VERSION "1.0"

NS_ :

BS_:

BU_: Transmitter

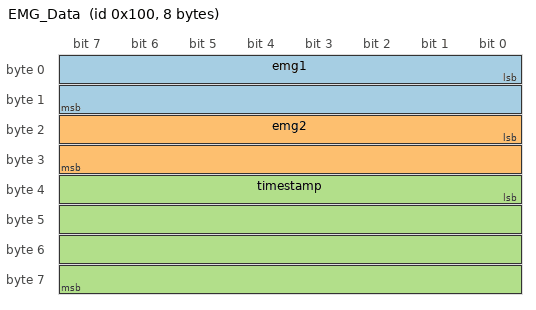
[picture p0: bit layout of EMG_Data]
BO_ 256 EMG_Data: 8 Transmitter
 SG_ emg1 : 0|16@1+ (1,0) [0|65535] "" Vector__XXX
 SG_ emg2 : 16|16@1+ (1,0) [0|65535] "" Vector__XXX
 SG_ timestamp : 32|32@1+ (1,0) [0|4294967295] "ms" Vector__XXX

BO_ 257 HeartRate_Data: 8 Transmitter
 SG_ heart_rate : 0|8@1+ (1,0) [0|255] "bpm" Vector__XXX
 SG_ timestamp : 8|32@1+ (1,0) [0|4294967295] "ms" Vector__XXX

CM_ SG_ 256 emg1 "EMG sensor 1 value (raw)";
CM_ SG_ 256 emg2 "EMG sensor 2 value (raw)";
CM_ SG_ 256 timestamp "Timestamp of EMG reading (ms)";
CM_ SG_ 257 heart_rate "Heart rate value (bpm)";
CM_ SG_ 257 timestamp "Timestamp of heart rate reading (ms)";
